# S6E2CC register map
File version: 1.1
CPU: 
Registers are 8-bit, read-write, reset 0x0 unless marked. A register's access mark holds for its fields unless they carry their own. Offsets are from the block's base; [hi:lo] are bit positions; {n}, {i} and the like mark numbered series; 'fields as' and 'values as' point back to an identical list.

## INTREQ — Interrupts
Base 0x40031000
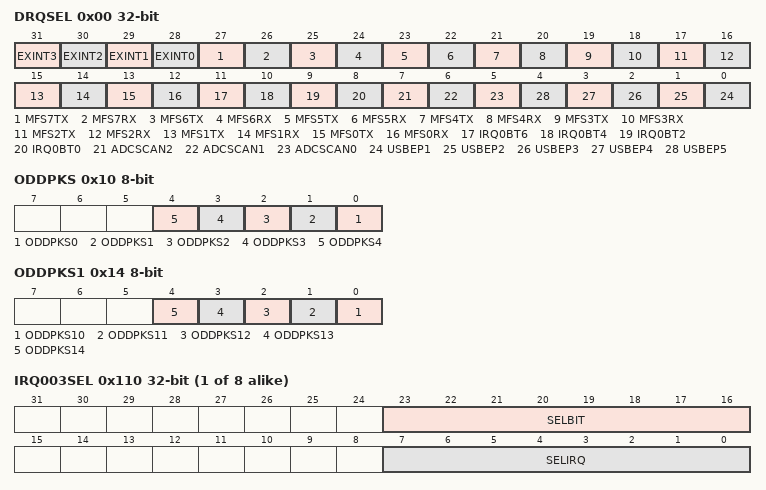
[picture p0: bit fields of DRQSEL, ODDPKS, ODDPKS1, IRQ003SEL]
0x00 DRQSEL 32-bit — DMA Request Selection Register
  [31] EXINT3 — External pin interrupt ch.3
  [30] EXINT2 — External pin interrupt ch.2
  [29] EXINT1 — External pin interrupt ch.1
  [28] EXINT0 — External pin interrupt ch.0
  [27] MFS7TX — MFS ch.7 transmission interrupt
  [26] MFS7RX — MFS ch.7 reception interrupt
  [25] MFS6TX — MFS ch.6 transmission interrupt
  [24] MFS6RX — MFS ch.6 reception interrupt
  [23] MFS5TX — MFS ch.5 transmission interrupt
  [22] MFS5RX — MFS ch.5 reception interrupt
  [21] MFS4TX — MFS ch.4 transmission interrupt
  [20] MFS4RX — MFS ch.4 reception interrupt
  [19] MFS3TX — MFS ch.3 transmission interrupt
  [18] MFS3RX — MFS ch.3 reception interrupt
  [17] MFS2TX — MFS ch.2 transmission interrupt
  [16] MFS2RX — MFS ch.2 reception interrupt
  [15] MFS1TX — MFS ch.1 transmission interrupt
  [14] MFS1RX — MFS ch.1 reception interrupt
  [13] MFS0TX — MFS ch.0 transmission interrupt
  [12] MFS0RX — MFS ch.0 reception interrupt.
  [11] IRQ0BT6 — Base timer ch.6 source 0 (IRQ0) interrupt
  [10] IRQ0BT4 — Base timer ch.4 source 0 (IRQ0) interrupt
  [9] IRQ0BT2 — Base timer ch.2 source 0 (IRQ0) interrupt
  [8] IRQ0BT0 — Base timer ch.6 source 0 (IRQ0) interrupt
  [7] ADCSCAN2 — A/D converter unit 2 scan conversion interrupt
  [6] ADCSCAN1 — A/D converter unit 1 scan conversion interrupt
  [5] ADCSCAN0 — A/D converter unit 0 scan conversion interrupt
  [n-1] USBEP{n} (n=1..5) — USB ch.0 function endpoint {n} DRQ interrupt
0x10 ODDPKS — USB ch.0 Odd Packet Size DMA Enable Register
  [n] ODDPKS{n} (n=0..4) — "If the transfer destination address of DMAC is USB.EP{n+1}DT, the bit width of the last transfer data is converted to Byte."
0x14 ODDPKS1 — USB ch.1 Odd Packet Size DMA Enable Register
  [n-10] ODDPKS{n} (n=10..14) — "If the transfer destination address of DMAC is USB.EP{n-9}DT, the bit width of the last transfer data is converted to Byte."
{0x104+4i} IRQ{i:03}SEL 32-bit (i=3..10) — Relocate Interrupt Selection Register (IRQ{i:03})
  [23:16] SELBIT — Bit7 of the interrupt source is moved to bit7 of the relocate interrupt.
  [7:0] SELIRQ — specify the IRQ no. of a peripheral interrupt to be relocated
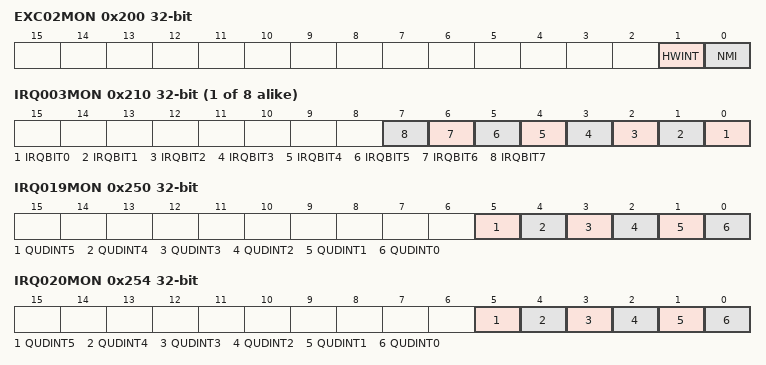
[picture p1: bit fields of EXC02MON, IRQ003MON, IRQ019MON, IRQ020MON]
0x200 EXC02MON 32-bit ro — EXC02 batch read register
  [1] HWINT — Interrupt request of the hardware watchdog timer
  [0] NMI — Interrupt request of the NMIX external pin
0x204 IRQ000MON 32-bit ro — IRQ000 Batch Read Register
  [0] FCSINT — Interrupt request of the anomalous frequency detected by the CSV
0x208 IRQ001MON 32-bit ro — IRQ001 Batch Read Register
  [0] SWWDTINT — interrupt request of the software watchdog timer
0x20C IRQ002MON 32-bit ro — IRQ002 Batch Read Register
  [0] LVDINT — Low-voltage detection (LVD) interrupt request
{0x204+4i} IRQ{i:03}MON 32-bit ro (i=3..10) — IRQ{i:03} Batch Read Register
  [n] IRQBIT{n} (n=0..7) — interrupt request of the interrupt selected in bit{n} of IRQ{i:03}SEL Register
0x230 IRQ011MON 32-bit ro — IRQ011 Batch Read Register
  [0] EXTINT — Interrupt request of the external pin interrupt ch.0
0x234 IRQ012MON 32-bit ro — IRQ012 Batch Read Register
  [0] EXTINT — Interrupt request of the external pin interrupt ch.1
0x238 IRQ013MON 32-bit ro — IRQ013 Batch Read Register
  [0] EXTINT — Interrupt request of the external pin interrupt ch.2
0x23C IRQ014MON 32-bit ro — IRQ014 Batch Read Register
  [0] EXTINT — Interrupt request of the external pin interrupt ch.3
0x240 IRQ015MON 32-bit ro — IRQ015 Batch Read Register
  [0] EXTINT — Interrupt request of the external pin interrupt ch.4
0x244 IRQ016MON 32-bit ro — IRQ016 Batch Read Register
  [0] EXTINT — Interrupt request of the external pin interrupt ch.5
0x248 IRQ017MON 32-bit ro — IRQ017 Batch Read Register
  [0] EXTINT — Interrupt request of the external pin interrupt ch.6
0x24C IRQ018MON 32-bit ro — IRQ018 Batch Read Register
  [0] EXTINT — Interrupt request of the external pin interrupt ch.7
0x250 IRQ019MON 32-bit ro — IRQ019 Batch Read Register
  [5] QUDINT5 — PC match and RC match interrupt request of QPRC ch.0
  [4] QUDINT4 — Out-of-range interrupt request of QPRC ch.0QPRC ch.0
  [3] QUDINT3 — Count inversion interrupt request of QPRC ch.0
  [2] QUDINT2 — Overflow / underflow / zero index interrupt request of QPRC ch.0
  [1] QUDINT1 — PC and RC match interrupt request of QPRC ch.0
  [0] QUDINT0 — PC match interrupt request of QPRC ch.0
0x254 IRQ020MON 32-bit ro — IRQ020 Batch Read Register
  [5] QUDINT5 — PC match and RC match interrupt request of QPRC ch.1
  [4] QUDINT4 — Out-of-range interrupt request of QPRC ch.1QPRC ch.1
  [3] QUDINT3 — Count inversion interrupt request of QPRC ch.1
  [2] QUDINT2 — Overflow / underflow / zero index interrupt request of QPRC ch.1
  [1] QUDINT1 — PC and RC match interrupt request of QPRC ch.1
  [0] QUDINT0 — PC match interrupt request of QPRC ch.1
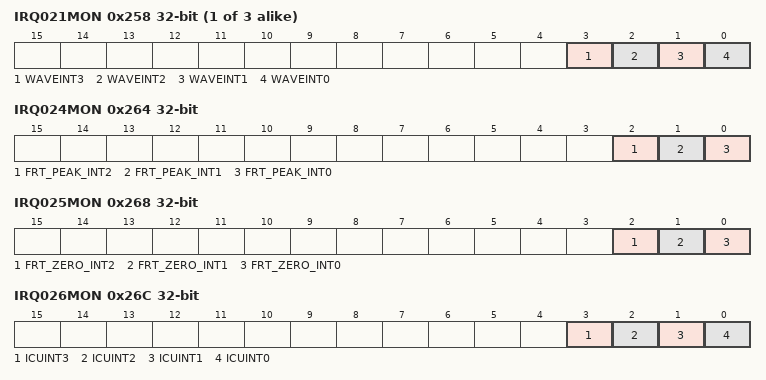
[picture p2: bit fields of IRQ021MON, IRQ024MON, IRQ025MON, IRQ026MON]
{0x204+4i} IRQ{i:03}MON 32-bit ro (i=21..23) — IRQ{i:03} Batch Read Register
  [3] WAVEINT3 — Interrupt request of WFG timer 54 of the MFT unit {i-21}
  [2] WAVEINT2 — Interrupt request of WFG timer 32 of the MFT unit {i-21}
  [1] WAVEINT1 — Interrupt request of WFG timer 10 of the MFT unit {i-21}
  [0] WAVEINT0 — Interrupt request of the DTIF (motor emergency stop) of the MFT unit {i-21}
0x264 IRQ024MON 32-bit ro — IRQ024 Batch Read Register
  [2] FRT_PEAK_INT2 — FRT ch.2 peak value detection interrupt request of the MFT unit 0
  [1] FRT_PEAK_INT1 — FRT ch.1 peak value detection interrupt request of the MFT unit 0
  [0] FRT_PEAK_INT0 — FRT ch.0 peak value detection interrupt request of the MFT unit 0
0x268 IRQ025MON 32-bit ro — IRQ025 Batch Read Register
  [2] FRT_ZERO_INT2 — FRT ch.2 zero detection interrupt request of the MFT unit 0
  [1] FRT_ZERO_INT1 — FRT ch.1 zero detection interrupt request of the MFT unit 0
  [0] FRT_ZERO_INT0 — FRT ch.0 zero detection interrupt request of the MFT unit 0
0x26C IRQ026MON 32-bit ro — IRQ026 Batch Read Register
  [3] ICUINT3 — ICU ch.3 input edge detection interrupt request of the MFT unit 0
  [2] ICUINT2 — ICU ch.2 input edge detection interrupt request of the MFT unit 0
  [1] ICUINT1 — ICU ch.1 input edge detection interrupt request of the MFT unit 0
  [0] ICUINT0 — ICU ch.0 input edge detection interrupt request of the MFT unit 0
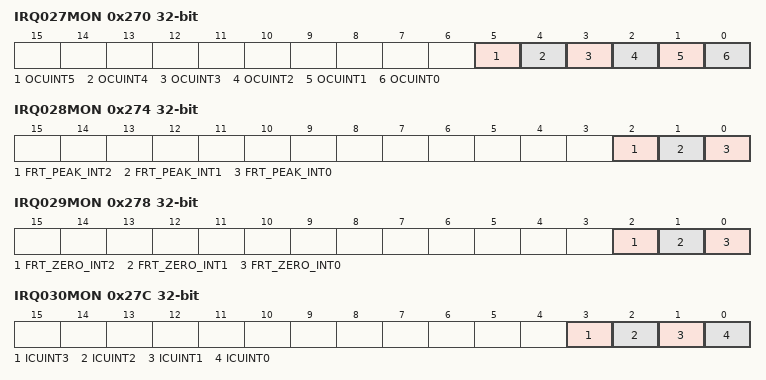
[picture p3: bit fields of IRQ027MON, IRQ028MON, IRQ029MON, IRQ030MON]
0x270 IRQ027MON 32-bit ro — IRQ027 Batch Read Register
  [5] OCUINT5 — OCU ch.5 match detection interrupt request of the MFT unit 0
  [4] OCUINT4 — OCU ch.4 match detection interrupt request of the MFT unit 0
  [3] OCUINT3 — OCU ch.3 match detection interrupt request of the MFT unit 0
  [2] OCUINT2 — OCU ch.2 match detection interrupt request of the MFT unit 0
  [1] OCUINT1 — OCU ch.1 match detection interrupt request of the MFT unit 0
  [0] OCUINT0 — OCU ch.0 match detection interrupt request of the MFT unit 0
0x274 IRQ028MON 32-bit ro — IRQ028 Batch Read Register
  [2] FRT_PEAK_INT2 — FRT ch.2 peak value detection interrupt request of the MFT unit 1
  [1] FRT_PEAK_INT1 — FRT ch.1 peak value detection interrupt request of the MFT unit 1
  [0] FRT_PEAK_INT0 — FRT ch.0 peak value detection interrupt request of the MFT unit 1
0x278 IRQ029MON 32-bit ro — IRQ029 Batch Read Register
  [2] FRT_ZERO_INT2 — FRT ch.2 zero detection interrupt request of the MFT unit 1
  [1] FRT_ZERO_INT1 — FRT ch.1 zero detection interrupt request of the MFT unit 1
  [0] FRT_ZERO_INT0 — FRT ch.0 zero detection interrupt request of the MFT unit 1
0x27C IRQ030MON 32-bit ro — IRQ030 Batch Read Register
  [3] ICUINT3 — ICU ch.3 input edge detection interrupt request of the MFT unit 1
  [2] ICUINT2 — ICU ch.2 input edge detection interrupt request of the MFT unit 1
  [1] ICUINT1 — ICU ch.1 input edge detection interrupt request of the MFT unit 1
  [0] ICUINT0 — ICU ch.0 input edge detection interrupt request of the MFT unit 1
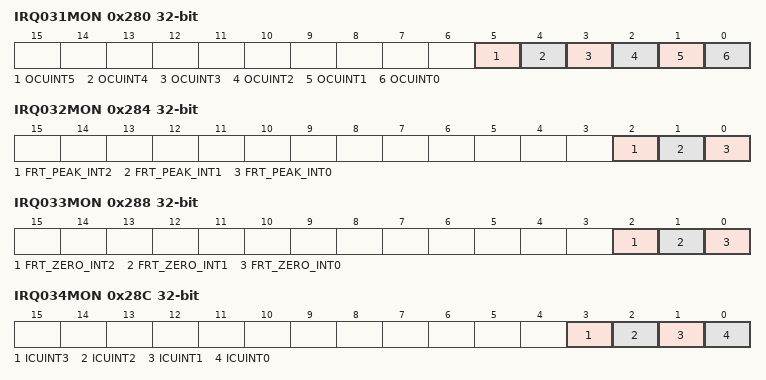
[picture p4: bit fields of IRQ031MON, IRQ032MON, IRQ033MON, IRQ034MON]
0x280 IRQ031MON 32-bit ro — IRQ031 Batch Read Register
  [5] OCUINT5 — OCU ch.5 match detection interrupt request of the MFT unit 1
  [4] OCUINT4 — OCU ch.4 match detection interrupt request of the MFT unit 1
  [3] OCUINT3 — OCU ch.3 match detection interrupt request of the MFT unit 1
  [2] OCUINT2 — OCU ch.2 match detection interrupt request of the MFT unit 1
  [1] OCUINT1 — OCU ch.1 match detection interrupt request of the MFT unit 1
  [0] OCUINT0 — OCU ch.0 match detection interrupt request of the MFT unit 1
0x284 IRQ032MON 32-bit ro — IRQ032 Batch Read Register
  [2] FRT_PEAK_INT2 — FRT ch.2 peak value detection interrupt request of the MFT unit 2
  [1] FRT_PEAK_INT1 — FRT ch.1 peak value detection interrupt request of the MFT unit 2
  [0] FRT_PEAK_INT0 — FRT ch.0 peak value detection interrupt request of the MFT unit 2
0x288 IRQ033MON 32-bit ro — IRQ033 Batch Read Register
  [2] FRT_ZERO_INT2 — FRT ch.2 zero detection interrupt request of the MFT unit 2
  [1] FRT_ZERO_INT1 — FRT ch.1 zero detection interrupt request of the MFT unit 2
  [0] FRT_ZERO_INT0 — FRT ch.0 zero detection interrupt request of the MFT unit 2
0x28C IRQ034MON 32-bit ro — IRQ034 Batch Read Register
  [3] ICUINT3 — ICU ch.3 input edge detection interrupt request of the MFT unit 2
  [2] ICUINT2 — ICU ch.2 input edge detection interrupt request of the MFT unit 2
  [1] ICUINT1 — ICU ch.1 input edge detection interrupt request of the MFT unit 2
  [0] ICUINT0 — ICU ch.0 input edge detection interrupt request of the MFT unit 2
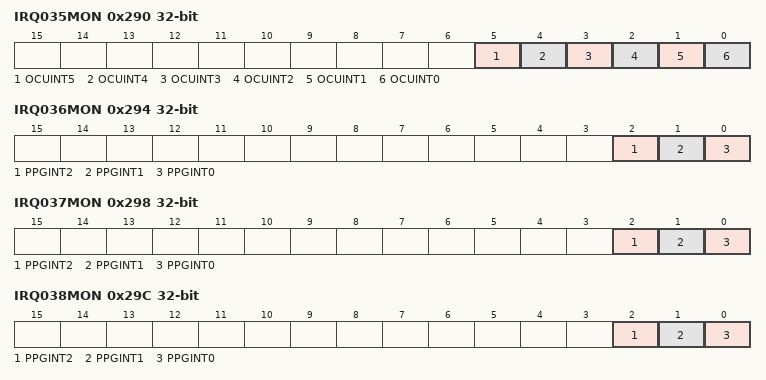
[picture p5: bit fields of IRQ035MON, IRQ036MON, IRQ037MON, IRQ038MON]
0x290 IRQ035MON 32-bit ro — IRQ035 Batch Read Register
  [5] OCUINT5 — OCU ch.5 match detection interrupt request of the MFT unit 2
  [4] OCUINT4 — OCU ch.4 match detection interrupt request of the MFT unit 2
  [3] OCUINT3 — OCU ch.3 match detection interrupt request of the MFT unit 2
  [2] OCUINT2 — OCU ch.2 match detection interrupt request of the MFT unit 2
  [1] OCUINT1 — OCU ch.1 match detection interrupt request of the MFT unit 2
  [0] OCUINT0 — OCU ch.0 match detection interrupt request of the MFT unit 2
0x294 IRQ036MON 32-bit ro — IRQ036 Batch Read Register
  [2] PPGINT2 — Interrupt request of the PPG ch.4
  [1] PPGINT1 — Interrupt request of the PPG ch.2
  [0] PPGINT0 — Interrupt request of the PPG ch.0
0x298 IRQ037MON 32-bit ro — IRQ037 Batch Read Register
  [2] PPGINT2 — Interrupt request of the PPG ch.12
  [1] PPGINT1 — Interrupt request of the PPG ch.10
  [0] PPGINT0 — Interrupt request of the PPG ch.8
0x29C IRQ038MON 32-bit ro — IRQ038 Batch Read Register
  [2] PPGINT2 — Interrupt request of the PPG ch.20
  [1] PPGINT1 — Interrupt request of the PPG ch.18
  [0] PPGINT0 — Interrupt request of the PPG ch.16
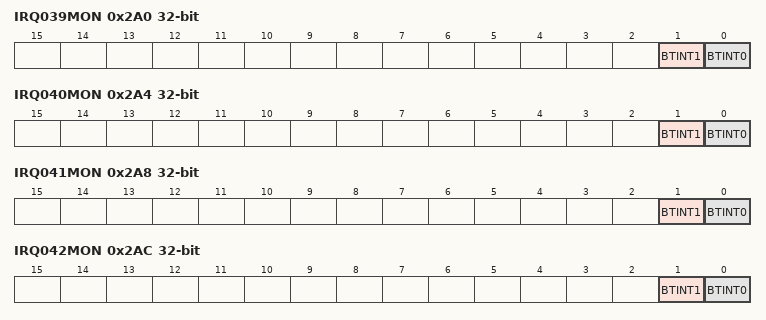
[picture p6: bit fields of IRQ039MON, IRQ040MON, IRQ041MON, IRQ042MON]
0x2A0 IRQ039MON 32-bit ro — IRQ039 Batch Read Register
  [1] BTINT1 — Interrupt request of source 1 (IRQ1) of the base timer ch.0
  [0] BTINT0 — Interrupt request of source 0 (IRQ0) of the base timer ch.0
0x2A4 IRQ040MON 32-bit ro — IRQ040 Batch Read Register
  [1] BTINT1 — Interrupt request of source 1 (IRQ1) of the base timer ch.1
  [0] BTINT0 — Interrupt request of source 0 (IRQ0) of the base timer ch.1
0x2A8 IRQ041MON 32-bit ro — IRQ041 Batch Read Register
  [1] BTINT1 — Interrupt request of source 1 (IRQ1) of the base timer ch.2
  [0] BTINT0 — Interrupt request of source 0 (IRQ0) of the base timer ch.2
0x2AC IRQ042MON 32-bit ro — IRQ042 Batch Read Register
  [1] BTINT1 — Interrupt request of source 1 (IRQ1) of the base timer ch.3
  [0] BTINT0 — Interrupt request of source 0 (IRQ0) of the base timer ch.3
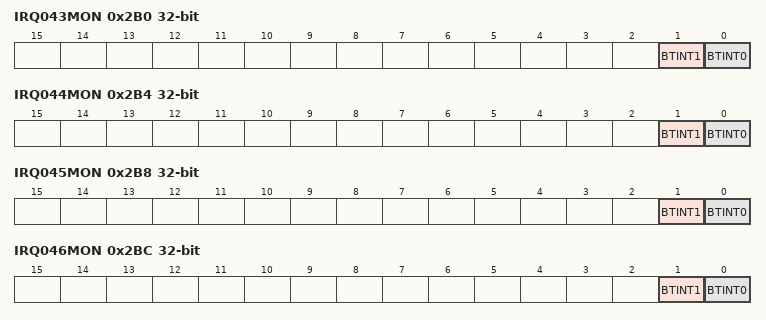
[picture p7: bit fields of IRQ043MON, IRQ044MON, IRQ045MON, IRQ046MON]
0x2B0 IRQ043MON 32-bit ro — IRQ043 Batch Read Register
  [1] BTINT1 — Interrupt request of source 1 (IRQ1) of the base timer ch.4
  [0] BTINT0 — Interrupt request of source 0 (IRQ0) of the base timer ch.4
0x2B4 IRQ044MON 32-bit ro — IRQ044 Batch Read Register
  [1] BTINT1 — Interrupt request of source 1 (IRQ1) of the base timer ch.5
  [0] BTINT0 — Interrupt request of source 0 (IRQ0) of the base timer ch.5
0x2B8 IRQ045MON 32-bit ro — IRQ045 Batch Read Register
  [1] BTINT1 — Interrupt request of source 1 (IRQ1) of the base timer ch.6
  [0] BTINT0 — Interrupt request of source 0 (IRQ0) of the base timer ch.6
0x2BC IRQ046MON 32-bit ro — IRQ046 Batch Read Register
  [1] BTINT1 — Interrupt request of source 1 (IRQ1) of the base timer ch.7
  [0] BTINT0 — Interrupt request of source 0 (IRQ0) of the base timer ch.7
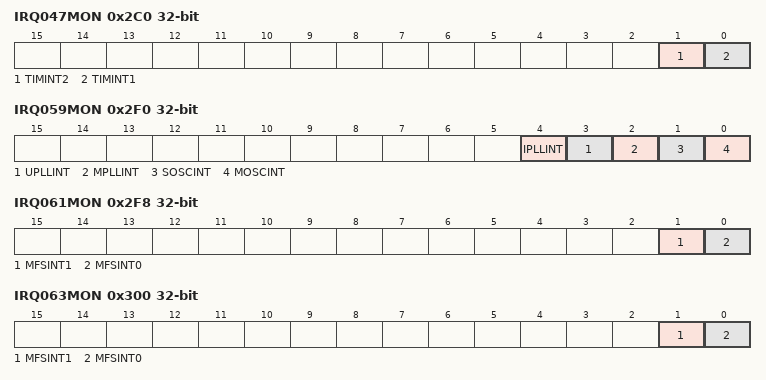
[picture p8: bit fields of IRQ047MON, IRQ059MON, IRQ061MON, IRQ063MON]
0x2C0 IRQ047MON 32-bit ro — IRQ047 Batch Read Register
  [1] TIMINT2 — Dual timer TIMINT2 interrupt request
  [0] TIMINT1 — Dual timer TIMINT1 interrupt request
0x2C4 IRQ048MON 32-bit ro — IRQ048 Batch Read Register
  [0] WCINT — Interrupt request of the watch counter
0x2C8 IRQ049MON 32-bit ro — IRQ049 Batch Read Register
  [0] BMEMCS — External bus output error interrupt request
0x2CC IRQ050MON 32-bit ro — IRQ050 Batch Read Register
  [0] RTCINT — Interrupt request of the RTC$
0x2D0 IRQ051MON 32-bit ro — IRQ051 Batch Read Register
  [0] EXTINT — Interrupt request of the external pin interrupt ch.8
0x2D4 IRQ052MON 32-bit ro — IRQ052 Batch Read Register
  [0] EXTINT — Interrupt request of the external pin interrupt ch.9
0x2D8 IRQ053MON 32-bit ro — IRQ053 Batch Read Register
  [0] EXTINT — Interrupt request of the external pin interrupt ch.10
0x2DC IRQ054MON 32-bit ro — IRQ054 Batch Read Register
  [0] EXTINT — Interrupt request of the external pin interrupt ch.11
0x2E0 IRQ055MON 32-bit ro — IRQ055 Batch Read Register
  [0] EXTINT — Interrupt request of the external pin interrupt ch.12
0x2E4 IRQ056MON 32-bit ro — IRQ056 Batch Read Register
  [0] EXTINT — Interrupt request of the external pin interrupt ch.13
0x2E8 IRQ057MON 32-bit ro — IRQ057 Batch Read Register
  [0] EXTINT — Interrupt request of the external pin interrupt ch.14
0x2EC IRQ058MON 32-bit ro — IRQ058 Batch Read Register
  [0] EXTINT — Interrupt request of the external pin interrupt ch.15
0x2F0 IRQ059MON 32-bit ro — IRQ059 Batch Read Register
  [4] IPLLINT — PLL of I2S oscillation stabilization wait completion interrupt
  [3] UPLLINT — PLL of USB / Ethernet oscillation stabilization wait completion interrupt
  [2] MPLLINT — Main PLL oscillation stabilization wait completion interrupt
  [1] SOSCINT — Sub clock oscillation stabilization wait completion interrupt
  [0] MOSCINT — Main clock oscillation stabilization wait completion interrupt
0x2F4 IRQ060MON 32-bit ro — IRQ060 Batch Read Register
  [0] MFSRINT — Reception interrupt request of the MFS ch.0
0x2F8 IRQ061MON 32-bit ro — IRQ061 Batch Read Register
  [1] MFSINT1 — Status interrupt request of the MFS ch.0
  [0] MFSINT0 — Transmission interrupt request of the MFS ch.0
0x2FC IRQ062MON 32-bit ro — IRQ062 Batch Read Register
  [0] MFSRINT — Reception interrupt request of the MFS ch.1
0x300 IRQ063MON 32-bit ro — IRQ063 Batch Read Register
  [1] MFSINT1 — Status interrupt request of the MFS ch.1
  [0] MFSINT0 — Transmission interrupt request of the MFS ch.1
0x304 IRQ064MON 32-bit ro — IRQ064 Batch Read Register
  [0] MFSRINT — Reception interrupt request of the MFS ch.2
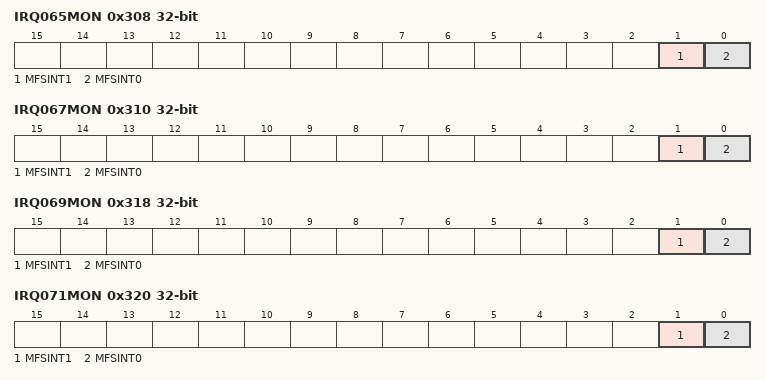
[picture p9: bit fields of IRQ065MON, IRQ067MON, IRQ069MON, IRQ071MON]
0x308 IRQ065MON 32-bit ro — IRQ065 Batch Read Register
  [1] MFSINT1 — Status interrupt request of the MFS ch.2
  [0] MFSINT0 — Transmission interrupt request of the MFS ch.2
0x30C IRQ066MON 32-bit ro — IRQ066 Batch Read Register
  [0] MFSRINT — Reception interrupt request of the MFS ch.3
0x310 IRQ067MON 32-bit ro — IRQ067 Batch Read Register
  [1] MFSINT1 — Status interrupt request of the MFS ch.3
  [0] MFSINT0 — Transmission interrupt request of the MFS ch.3
0x314 IRQ068MON 32-bit ro — IRQ068 Batch Read Register
  [0] MFSRINT — Reception interrupt request of the MFS ch.4
0x318 IRQ069MON 32-bit ro — IRQ069 Batch Read Register
  [1] MFSINT1 — Status interrupt request of the MFS ch.4
  [0] MFSINT0 — Transmission interrupt request of the MFS ch.4
0x31C IRQ070MON 32-bit ro — IRQ070 Batch Read Register
  [0] MFSRINT — Reception interrupt request of the MFS ch.5
0x320 IRQ071MON 32-bit ro — IRQ071 Batch Read Register
  [1] MFSINT1 — Status interrupt request of the MFS ch.5
  [0] MFSINT0 — Transmission interrupt request of the MFS ch.5
0x324 IRQ072MON 32-bit ro — IRQ072 Batch Read Register
  [0] MFSRINT — Reception interrupt request of the MFS ch.6
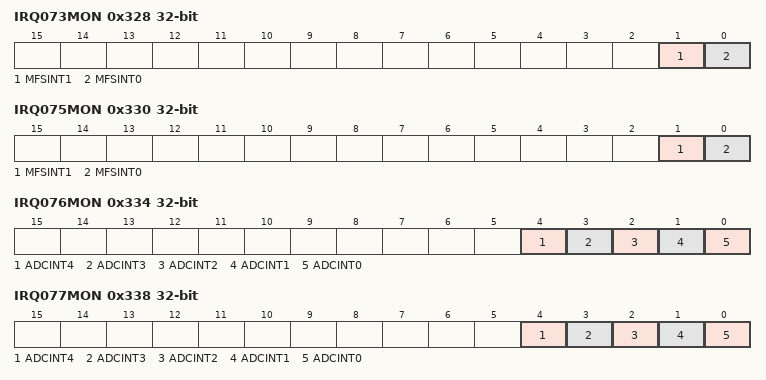
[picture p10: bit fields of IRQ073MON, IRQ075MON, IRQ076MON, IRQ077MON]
0x328 IRQ073MON 32-bit ro — IRQ073 Batch Read Register
  [1] MFSINT1 — Status interrupt request of the MFS ch.6
  [0] MFSINT0 — Transmission interrupt request of the MFS ch.6
0x32C IRQ074MON 32-bit ro — IRQ074 Batch Read Register
  [0] MFSRINT — Reception interrupt request of the MFS ch.7
0x330 IRQ075MON 32-bit ro — IRQ075 Batch Read Register
  [1] MFSINT1 — Status interrupt request of the MFS ch.7
  [0] MFSINT0 — Transmission interrupt request of the MFS ch.7
0x334 IRQ076MON 32-bit ro — IRQ076 Batch Read Register
  [4] ADCINT4 — Range comparison result interrupt request of the A/D converter unit 0
  [3] ADCINT3 — Conversion result comparison interrupt request of the A/D converter unit 0
  [2] ADCINT2 — FIFO overrun interrupt request of the A/D converter unit 0
  [1] ADCINT1 — Scan conversion interrupt request of the A/D converter unit 0
  [0] ADCINT0 — Priority conversion interrupt request of the A/D converter unit 0
0x338 IRQ077MON 32-bit ro — IRQ077 Batch Read Register
  [4] ADCINT4 — Range comparison result interrupt request of the A/D converter unit 1
  [3] ADCINT3 — Conversion result comparison interrupt request of the A/D converter unit 1
  [2] ADCINT2 — FIFO overrun interrupt request of the A/D converter unit 1
  [1] ADCINT1 — Scan conversion interrupt request of the A/D converter unit 1
  [0] ADCINT0 — Priority conversion interrupt request of the A/D converter unit 1
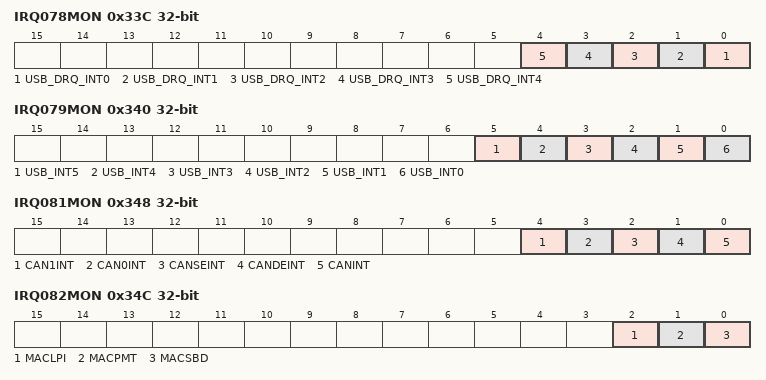
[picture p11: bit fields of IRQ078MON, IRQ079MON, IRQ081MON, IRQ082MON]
0x33C IRQ078MON 32-bit ro — IRQ078 Batch Read Register
  [n] USB_DRQ_INT{n} (n=0..4) — Endpoint {n+1} DRQ interrupt request of the USB ch.0
0x340 IRQ079MON 32-bit ro — IRQ079 Batch Read Register
  [5] USB_INT5 — SOFIRQ/CMPIRQ interrupt request of the USB ch.0
  [4] USB_INT4 — DIRQ/URPIRQ/RWKIRQ/CNNIRQ interrupt request of the USB ch.0
  [3] USB_INT3 — SPK interrupt request of the USB ch.0
  [2] USB_INT2 — SUSP/SOF/BRST/CONF/WKUP interrupt request of the USB ch.0
  [1] USB_INT1 — Endpoint 0 DRQO interrupt request of the USB ch.0
  [0] USB_INT0 — Endpoint 0 DRQI interrupt request of the USB ch.0
0x344 IRQ080MON 32-bit ro — IRQ080 Batch Read Register
  [0] CANINT — Interrupt request of the CAN ch.0
0x348 IRQ081MON 32-bit ro — IRQ081 Batch Read Register
  [4] CAN1INT — CAN-FD 1 interrupt request
  [3] CAN0INT — CAN-FD 0 interrupt request
  [2] CANSEINT — Single bit error interrupt request of the CAN-FD
  [1] CANDEINT — Double bit error interrupt request of the CAN-FD
  [0] CANINT — Interrupt request of the CAN ch.1
0x34C IRQ082MON 32-bit ro — IRQ082 Batch Read Register
  [2] MACLPI — LPI interrupt request of the Ethernet MAC
  [1] MACPMT — PMT interrupt request of the Ethernet MAC
  [0] MACSBD — SBD interrupt request of the Ethernet MAC
0x350 IRQ083MON 32-bit ro — IRQ083 Batch Read Register
  [0] DMACINT — Interrupt request of the DMAC ch.0
0x354 IRQ084MON 32-bit ro — IRQ084 Batch Read Register
  [0] DMACINT — Interrupt request of the DMAC ch.1
0x358 IRQ085MON 32-bit ro — IRQ085 Batch Read Register
  [0] DMACINT — Interrupt request of the DMAC ch.2
0x35C IRQ086MON 32-bit ro — IRQ086 Batch Read Register
  [0] DMACINT — Interrupt request of the DMAC ch.3
0x360 IRQ087MON 32-bit ro — IRQ087 Batch Read Register
  [0] DMACINT — Interrupt request of the DMAC ch.4
0x364 IRQ088MON 32-bit ro — IRQ088 Batch Read Register
  [0] DMACINT — Interrupt request of the DMAC ch.5
0x368 IRQ089MON 32-bit ro — IRQ089 Batch Read Register
  [0] DMACINT — Interrupt request of the DMAC ch.6
0x36C IRQ090MON 32-bit ro — IRQ090 Batch Read Register
  [0] DMACINT — Interrupt request of the DMAC ch.7
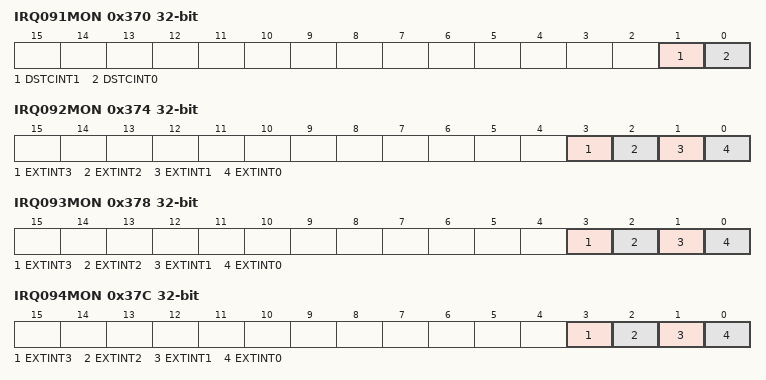
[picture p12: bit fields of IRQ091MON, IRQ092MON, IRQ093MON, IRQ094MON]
0x370 IRQ091MON 32-bit ro — IRQ091 Batch Read Register
  [1] DSTCINT1 — DSTC ERINT interrupt request
  [0] DSTCINT0 — DSTC SWINT interrupt request
0x374 IRQ092MON 32-bit ro — IRQ092 Batch Read Register
  [3] EXTINT3 — Interrupt request of the external pin interrupt ch.19
  [2] EXTINT2 — Interrupt request of the external pin interrupt ch.18
  [1] EXTINT1 — Interrupt request of the external pin interrupt ch.17
  [0] EXTINT0 — Interrupt request of the external pin interrupt ch.16
0x378 IRQ093MON 32-bit ro — IRQ093 Batch Read Register
  [3] EXTINT3 — Interrupt request of the external pin interrupt ch.23
  [2] EXTINT2 — Interrupt request of the external pin interrupt ch.22
  [1] EXTINT1 — Interrupt request of the external pin interrupt ch.21
  [0] EXTINT0 — Interrupt request of the external pin interrupt ch.20
0x37C IRQ094MON 32-bit ro — IRQ094 Batch Read Register
  [3] EXTINT3 — Interrupt request of the external pin interrupt ch.27
  [2] EXTINT2 — Interrupt request of the external pin interrupt ch.26
  [1] EXTINT1 — Interrupt request of the external pin interrupt ch.25
  [0] EXTINT0 — Interrupt request of the external pin interrupt ch.24
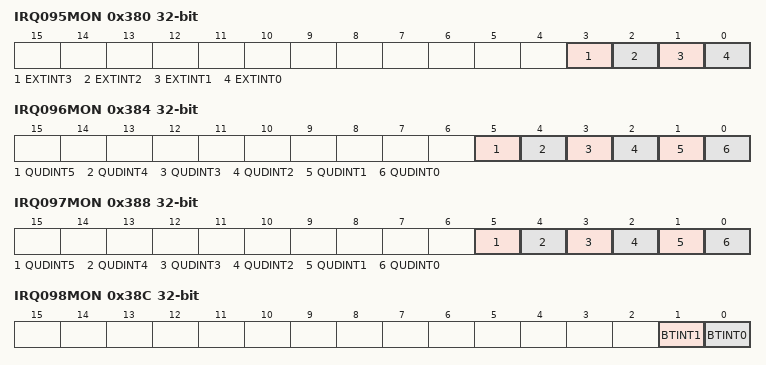
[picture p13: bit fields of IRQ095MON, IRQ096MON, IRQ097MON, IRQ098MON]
0x380 IRQ095MON 32-bit ro — IRQ095 Batch Read Register
  [3] EXTINT3 — Interrupt request of the external pin interrupt ch.31
  [2] EXTINT2 — Interrupt request of the external pin interrupt ch.30
  [1] EXTINT1 — Interrupt request of the external pin interrupt ch.29
  [0] EXTINT0 — Interrupt request of the external pin interrupt ch.28
0x384 IRQ096MON 32-bit ro — IRQ096 Batch Read Register
  [5] QUDINT5 — PC match and RC match interrupt request of QPRC ch.2
  [4] QUDINT4 — Out-of-range interrupt request of QPRC ch.2QPRC ch.2
  [3] QUDINT3 — Count inversion interrupt request of QPRC ch.2
  [2] QUDINT2 — Overflow / underflow / zero index interrupt request of QPRC ch.2
  [1] QUDINT1 — PC and RC match interrupt request of QPRC ch.2
  [0] QUDINT0 — PC match interrupt request of QPRC ch.2
0x388 IRQ097MON 32-bit ro — IRQ097 Batch Read Register
  [5] QUDINT5 — PC match and RC match interrupt request of QPRC ch.3
  [4] QUDINT4 — Out-of-range interrupt request of QPRC ch.3QPRC ch.3
  [3] QUDINT3 — Count inversion interrupt request of QPRC ch.3
  [2] QUDINT2 — Overflow / underflow / zero index interrupt request of QPRC ch.3
  [1] QUDINT1 — PC and RC match interrupt request of QPRC ch.3
  [0] QUDINT0 — PC match interrupt request of QPRC ch.3
0x38C IRQ098MON 32-bit ro — IRQ098 Batch Read Register
  [1] BTINT1 — Interrupt request of source 1 (IRQ1) of the base timer ch.8
  [0] BTINT0 — Interrupt request of source 0 (IRQ0) of the base timer ch.8
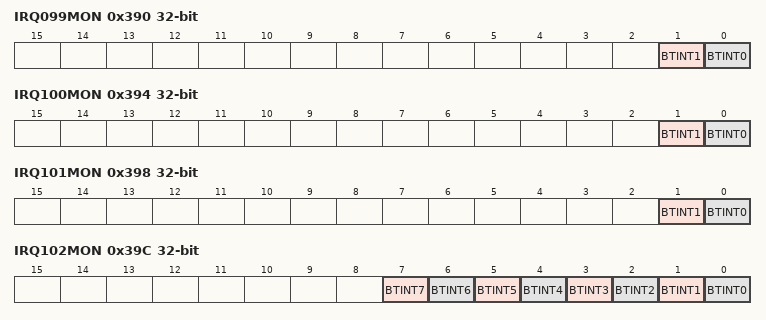
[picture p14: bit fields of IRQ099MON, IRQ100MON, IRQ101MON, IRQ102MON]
0x390 IRQ099MON 32-bit ro — IRQ099 Batch Read Register
  [1] BTINT1 — Interrupt request of source 1 (IRQ1) of the base timer ch.9
  [0] BTINT0 — Interrupt request of source 0 (IRQ0) of the base timer ch.9
0x394 IRQ100MON 32-bit ro — IRQ100 Batch Read Register
  [1] BTINT1 — Interrupt request of source 1 (IRQ1) of the base timer ch.10
  [0] BTINT0 — Interrupt request of source 0 (IRQ0) of the base timer ch.10
0x398 IRQ101MON 32-bit ro — IRQ101 Batch Read Register
  [1] BTINT1 — Interrupt request of source 1 (IRQ1) of the base timer ch.11
  [0] BTINT0 — Interrupt request of source 0 (IRQ0) of the base timer ch.11
0x39C IRQ102MON 32-bit ro — IRQ102 Batch Read Register
  [7] BTINT7 — Interrupt request of source 1 (IRQ1) of the base timer ch.15
  [6] BTINT6 — Interrupt request of source 0 (IRQ0) of the base timer ch.15
  [5] BTINT5 — Interrupt request of source 1 (IRQ1) of the base timer ch.14
  [4] BTINT4 — Interrupt request of source 0 (IRQ0) of the base timer ch.14
  [3] BTINT3 — Interrupt request of source 1 (IRQ1) of the base timer ch.13
  [2] BTINT2 — Interrupt request of source 0 (IRQ0) of the base timer ch.13
  [1] BTINT1 — Interrupt request of source 1 (IRQ1) of the base timer ch.12
  [0] BTINT0 — Interrupt request of source 0 (IRQ0) of the base timer ch.12
0x3A0 IRQ103MON 32-bit ro — IRQ103 Batch Read Register
  [0] MFSRINT — Reception interrupt request of the MFS ch.8
0x3A4 IRQ104MON 32-bit ro — IRQ104 Batch Read Register
  [1] MFSINT1 — Status interrupt request of the MFS ch.8
  [0] MFSINT0 — Transmission interrupt request of the MFS ch.8
0x3A8 IRQ105MON 32-bit ro — IRQ105 Batch Read Register
  [0] MFSRINT — Reception interrupt request of the MFS ch.9
0x3AC IRQ106MON 32-bit ro — IRQ106 Batch Read Register
  [1] MFSINT1 — Status interrupt request of the MFS ch.9
  [0] MFSINT0 — Transmission interrupt request of the MFS ch.9
0x3B0 IRQ107MON 32-bit ro — IRQ107 Batch Read Register
  [0] MFSRINT — Reception interrupt request of the MFS ch.10
0x3B4 IRQ108MON 32-bit ro — IRQ108 Batch Read Register
  [1] MFSINT1 — Status interrupt request of the MFS ch.10
  [0] MFSINT0 — Transmission interrupt request of the MFS ch.10
0x3B8 IRQ109MON 32-bit ro — IRQ109 Batch Read Register
  [0] MFSRINT — Reception interrupt request of the MFS ch.11
0x3BC IRQ110MON 32-bit ro — IRQ110 Batch Read Register
  [1] MFSINT1 — Status interrupt request of the MFS ch.11
  [0] MFSINT0 — Transmission interrupt request of the MFS ch.11
0x3C0 IRQ111MON 32-bit ro — IRQ111 Batch Read Register
  [4] ADCINT4 — Range comparison result interrupt request of the A/D converter unit 2
  [3] ADCINT3 — Conversion result comparison interrupt request of the A/D converter unit 2
  [2] ADCINT2 — FIFO overrun interrupt request of the A/D converter unit 2
  [1] ADCINT1 — Scan conversion interrupt request of the A/D converter unit 2
  [0] ADCINT0 — Priority conversion interrupt request of the A/D converter unit 2
0x3C4 IRQ112MON 32-bit ro — IRQ112 Batch Read Register
  [5] CANDINT — Interrupt request of DSTC transfer end interrupt of CAN-FD
  [4] PCRCDINT — Interrupt request of DSTC transfer end interrupt of Programmable CRC
  [3] QSPIDINT1 — Interrupt request of DSTC transfer end interrupt of Quad SPI(transmission)
  [2] QSPIDINT0 — Interrupt request of DSTC transfer end interrupt of Quad SPI(reception)
  [1] I2SDINT1 — Interrupt request of DSTC transfer end interrupt of I2S(transmission)
  [0] I2SDINT0 — Interrupt request of DSTC transfer end interrupt of I2S(reception)
0x3C8 IRQ113MON 32-bit ro — IRQ113 Batch Read Register
  [5] RCEC0INT — ERROR!!!!!!!!!!!!!!!!!!!!
  [n] USB_DRQ_INT{n} (n=0..4) — ERROR!!!!!!!!!!!!!!!!!!!!
0x3CC IRQ114MON 32-bit ro — ERROR!!!!!!!!!!!!!!!!!!!!
  [6] RCEC1INT — ERROR!!!!!!!!!!!!!!!!!!!!
  [n] USB_INT{n} (n=0..5) — ERROR!!!!!!!!!!!!!!!!!!!!
0x3D0 IRQ115MON 32-bit ro — ERROR!!!!!!!!!!!!!!!!!!!!
  [2] QSPIINT2 — ERROR!!!!!!!!!!!!!!!!!!!!
  [1] QSPIINT1 — ERROR!!!!!!!!!!!!!!!!!!!!
  [0] QSPIINT0 — ERROR!!!!!!!!!!!!!!!!!!!!
0x3D4 IRQ116MON 32-bit ro reset not defined — ERROR!!!!!!!!!!!!!!!!!!!!
0x3D8 IRQ117MON 32-bit ro — ERROR!!!!!!!!!!!!!!!!!!!!
  [1] PRGCRC — ERROR!!!!!!!!!!!!!!!!!!!!
  [0] I2SINT — ERROR!!!!!!!!!!!!!!!!!!!!
0x3DC IRQ118MON 32-bit ro — ERROR!!!!!!!!!!!!!!!!!!!!
  [1] SDINT1 — ERROR!!!!!!!!!!!!!!!!!!!!
  [0] SDINT0 — ERROR!!!!!!!!!!!!!!!!!!!!
0x3E0 IRQ119MON 32-bit ro — ERROR!!!!!!!!!!!!!!!!!!!!
  [0] FLINT
0x3E4 IRQ120MON 32-bit ro — ERROR!!!!!!!!!!!!!!!!!!!!
  [0] MFSRINT
0x3E8 IRQ121MON 32-bit ro — ERROR!!!!!!!!!!!!!!!!!!!!
  [1] MFSINT1 — ERROR!!!!!!!!!!!!!!!!!!!!
  [0] MFSINT0 — ERROR!!!!!!!!!!!!!!!!!!!!
0x3EC IRQ122MON 32-bit ro — ERROR!!!!!!!!!!!!!!!!!!!!
  [0] MFSRINT
0x3F0 IRQ123MON 32-bit ro — ERROR!!!!!!!!!!!!!!!!!!!!
  fields as IRQ121MON
0x3F4 IRQ124MON 32-bit ro — ERROR!!!!!!!!!!!!!!!!!!!!
  [0] MFSRINT
0x3F8 IRQ125MON 32-bit ro — ERROR!!!!!!!!!!!!!!!!!!!!
  fields as IRQ121MON
0x3FC IRQ126MON 32-bit ro — ERROR!!!!!!!!!!!!!!!!!!!!
  [0] MFSRINT
0x400 IRQ127MON 32-bit ro — ERROR!!!!!!!!!!!!!!!!!!!!
  fields as IRQ121MON
